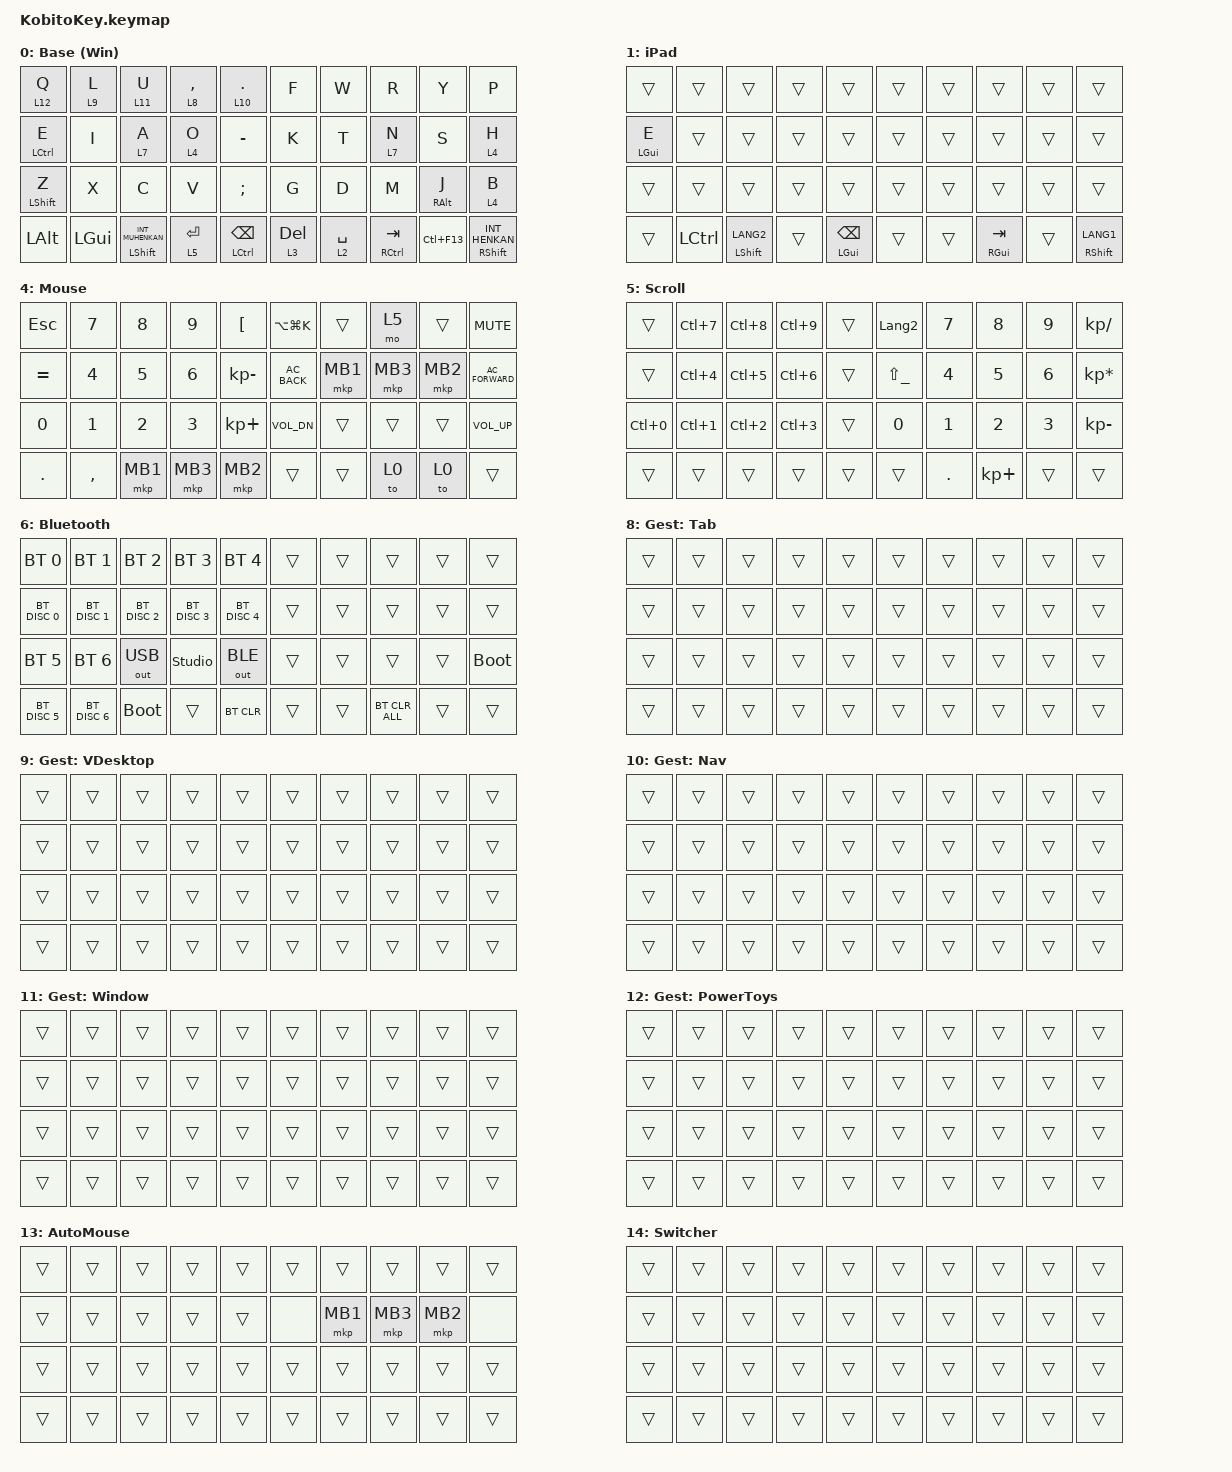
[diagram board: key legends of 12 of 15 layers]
/* 配列は torabo-tsuki LP (Daytona0306/zmk-keyboard-torabo-tsuki-lp) の移植。
 *
 * 文字キー30個は同じ位置。最下段は親指の内側から順に対応させた:
 *
 *   30 Alt   31 GUI   32 無変換/Shift  33 Enter/L5  34 BS/Ctrl
 *   35 Del/L3  36 Space/L2  37 変換/Shift   38 Ctrl+F13  39 Tab
 *
 * torabo-tsuki LP の外周・数字段・中央の追加キーは小人キーに無いので落としている。
 * レイヤー番号は torabo-tsuki LP と同じ (コンボ・ジェスチャー・overlay・conf が番号に依存)。 */
#include <behaviors.dtsi>
#include <dt-bindings/zmk/bt.h>
#include <dt-bindings/zmk/keys.h>
#include <dt-bindings/zmk/outputs.h>
#include <dt-bindings/zmk/pointing.h>
/* &rmacro <slot>。中身は DYA Studio のランタイムマクロパネルで記録する。 */
#include <behaviors/runtime_macro.dtsi>
/* &mg_set N。押している間だけ RPC 側のジェスチャーセットが有効になる。 */
#include <mouse-gesture-rpc.dtsi>

/* ジェスチャー定義は機種共通 (zmk-dya-common)。ジェスチャーは右ボール (カーソル側)。
 * BASE_LAYER は矢印ジェスチャーのレイヤー番号で、そこから連番で6枚使う。
 * TRANSFORM は 0 (変換なし): 右ボールのベースチェーンに軸反転が無いため。
 * ★実機未確認★ 上下左右が逆に出たらここを INPUT_TRANSFORM_*_INVERT にする。 */
#define DYA_GESTURE_LISTENER   tb_right_listener
#define DYA_GESTURE_BASE_LAYER 7
#define DYA_GESTURE_TRANSFORM  0
#include <dya-common/gestures.dtsi>

&mt {
    tapping-term-ms = <180>;
    quick-tap-ms = <300>;
    flavor = "tap-preferred";
    require-prior-idle-ms = <125>;
};

&lt {
    tapping-term-ms = <180>;
    quick-tap-ms = <300>;
    flavor = "tap-preferred";
    require-prior-idle-ms = <125>;
};

/* DYA Studio 用の「セット番号固定」ジェスチャーキー。
 *
 * Studio はパラメータ付きのカスタム behavior を保持できないため、汎用の
 * &mg_set N は Studio の一覧から割り当てられない。モジュール側は対策として
 * パラメータ無しの compatible "zmk,behavior-mg-set-fixed" を用意しているが、
 * ノード自体は定義していない (README にも記載なし) ので、ここで自前で作る。
 *
 * セット番号はノード名の末尾1文字から決まる (behavior_mg_set.c の
 * binding_set_id())。よってノード名は必ず _0 / _1 / _2 で終わらせること。
 * ドライバ側の判定が '0'..'2' 固定なので 3 セットまでしか作れない。
 *
 * 押している間だけジェスチャー判定が有効になり、離した時点で一致した
 * ジェスチャーが発火する。 */
/ {
    behaviors {
        mg_set_0: behavior_mg_set_0 {
            compatible = "zmk,behavior-mg-set-fixed";
            #binding-cells = <0>;
            display-name = "Mouse Gesture Key 0";
        };

        mg_set_1: behavior_mg_set_1 {
            compatible = "zmk,behavior-mg-set-fixed";
            #binding-cells = <0>;
            display-name = "Mouse Gesture Key 1";
        };

        mg_set_2: behavior_mg_set_2 {
            compatible = "zmk,behavior-mg-set-fixed";
            #binding-cells = <0>;
            display-name = "Mouse Gesture Key 2";
        };
    };
};

/* ジェスチャーキーの hold-tap 版。&mg_ht <セット> <キーコード> で
 * 「長押し＝ジェスチャー、タップ＝通常キー」になる。
 *
 * hold 側は固定版 (mg_set_0 等) ではなく汎用の &mg_set を使う。
 * hold-tap は子のメタデータを合成して自分の param1 の選択肢にするが、
 * 固定版は空メタデータなので param1 が選べなくなるため
 * (behavior_hold_tap.c の hold_tap_parameter_metadata())。
 * 汎用版ならセット番号が param1 としてそのまま渡り、名前末尾ではなく
 * パラメータ側で解決される。
 *
 * flavor は tap-preferred。ボールの動きは hold-tap の判定材料に
 * ならないため他フレーバーにする利点がなく、ストローク中に他キーへ
 * 触れても hold に化けないぶん安全。
 *
 * 制約: マッチャーが ON になるのは hold 確定後なので、押してから
 * tapping-term-ms のあいだのボール移動は通常のカーソル移動として出る。
 * 「押して即ストローク」はできない。専用キーに素の &mg_set を置いた
 * ほうが体感は良い。短くすると今度はタップを取りこぼす。 */
/ {
    behaviors {
        mg_ht: mouse_gesture_hold_tap {
            compatible = "zmk,behavior-hold-tap";
            #binding-cells = <2>;
            flavor = "tap-preferred";
            tapping-term-ms = <150>;
            bindings = <&mg_set>, <&kp>;
            display-name = "Mouse Gesture Hold-Tap";
        };
    };
};

/ {
    combos {
        compatible = "zmk,combos";

        tab {
            bindings = <&kp TAB>;
            key-positions = <10 11>;
        };

        esc {
            bindings = <&kp ESCAPE>;
            key-positions = <0 1>;
        };

        caps {
            bindings = <&kp CAPSLOCK>;
            key-positions = <20 21>;
        };

        BS {
            bindings = <&kp BACKSPACE>;
            key-positions = <8 9>;
        };

        LANG_2 {
            bindings = <&kp LANGUAGE_2>;
            key-positions = <12 13>;
        };

        LANG_1 {
            bindings = <&kp LANGUAGE_1>;
            key-positions = <16 17>;
        };

        Layer_6 {
            bindings = <&mo 6>;
            key-positions = <26 27>;
        };

        Layer_4 {
            bindings = <&mo 5>;
            key-positions = <27 28>;
        };

        /* Ctrl+Alt+Tab (Windows の固定タスクスイッチャー)。
         *
         * ★押した瞬間に Ctrl+Alt+Tab を1回だけ送って切り替え画面を開き、押している間は
         *   レイヤー 14 (Switcher) で左ボールが矢印キーになる (選択を動かす)。
         *   離すと Enter で決定する。中身は下の macros の win_switcher。
         *   以前は &kp LA(LC(TAB)) で押しっぱなしにしていたため、キーリピートで選択が右へ流れていた。
         *
         * ★このコンボは DYA Studio 側にも同じ内容で入れてある。
         *   そちらを有効にしていると毎回発動し、無効にすると効いたり
         *   効かなかったりする、という実機の結果がある。
         *   両方に同じ内容があるのは意図的。片方だけ直さないこと。
         *   経緯は README「コンボが keymap と DYA Studio の両方にあるとき、
         *   勝つ側はリンク順で決まる」と「同じコンボでも、DYA 側で持たせた
         *   ほうが安定することがある」。原因は未解明のまま打ち切った。
         *
         * timeout-ms は既定の 50 から広げてある。
         * これは上記の差の説明ではない (ランタイム側の既定も 50 で、
         * 2キーコンボの処理経路は両エンジンで等価)。
         * 純粋に、2/3 が上段の2キー同時押しで、ホームポジションにある
         * LANG_2 (12/13) より指が揃いにくいことへの手当て。
         *
         * 広げるコストは小さい。combo.c の position_state_up は離した時点で
         * cleanup() を呼んで取り込んだイベントを流すので、普通に U を打つぶんには
         * タイムアウトを待たされない。長押しでレイヤーに入るときだけ
         * timeout-ms 分だけ遅れる (200 + 80 = 280ms)。 */
        combo_ctrl_alt_tab {
            key-positions = <2 3>;
            bindings = <&win_switcher>;
            timeout-ms = <80>;
        };
    };

    macros {
        BrowsToExploree: BrowsToExploree {
            compatible = "zmk,behavior-macro";
            #binding-cells = <0>;
            bindings = <&kp LS(LA(B)) &kp ENTER &kp LG(NUMBER_1)>;
            label = "BROWSTOEXPLOREE";
        };

        /* ウィンドウ切り替え (Ctrl+Alt+Tab コンボ用)。
         * 押す: Ctrl+Alt+Tab を1回 → レイヤー 14 (Switcher) を有効にする
         * 押している間: 左ボールの上下左右が矢印キー (KobitoKey_left.overlay の route_switcher)
         * 離す: レイヤー 14 を切って Enter (選んだウィンドウに切り替わる) */
        win_switcher: win_switcher {
            compatible = "zmk,behavior-macro";
            #binding-cells = <0>;
            label = "WIN_SWITCHER";
            bindings
                = <&macro_tap &kp LC(LA(TAB))>
                , <&macro_press &mo 14>
                , <&macro_pause_for_release>
                , <&macro_release &mo 14>
                , <&macro_tap &kp ENTER>
                ;
        };

        to_layer_0: to_layer_0 {
            compatible = "zmk,behavior-macro-one-param";
            #binding-cells = <1>;
            bindings = <&to 0 &macro_param_1to1 &kp MACRO_PLACEHOLDER>;
            label = "TO_LAYER_0";
        };

    };

    behaviors {
        /* 文字キーの長押しでジェスチャーレイヤー (7〜12) に入るキー用の layer-tap。
         * A・N・Q・L・U・,・. に使う。親指 (Space/Del/Enter) と O/H/B (Mouse) は &lt のまま。
         *
         * 文字キーは打鍵中に頻繁に出るので、&lt より誤爆しにくい側に倒している。
         * 例: 寿司打で「ni」の N を少し長めに押すと、レイヤー 7 の I の位置の F5 が出て
         * ページが再読み込みされていた。
         *   - tapping-term 250ms: これより短く離せばタップ (tap-preferred なので押している長さだけで決まる)
         *   - require-prior-idle 200ms: 直前の打鍵から 200ms 以内に押したら、長押し判定をせずタップに確定
         * DYA Studio の dya__holdtap (mt/lt だけが対象) では変えられない。変えるときはここを書き換えて焼く。 */
        lt_gest: lt_gest {
            compatible = "zmk,behavior-hold-tap";
            display-name = "Layer-Tap (Gesture)";
            #binding-cells = <2>;
            bindings = <&mo>, <&kp>;
            flavor = "tap-preferred";
            tapping-term-ms = <250>;
            quick-tap-ms = <300>;
            require-prior-idle-ms = <200>;
        };

        lt_to_layer_0: lt_to_layer_0 {
            compatible = "zmk,behavior-hold-tap";
            label = "LAYER_TAP_TO_0";
            bindings = <&mo>, <&to_layer_0>;

            #binding-cells = <2>;
            tapping-term-ms = <180>;
        };
    };

    keymap {
        compatible = "zmk,keymap";

        default_layer {
            display-name = "Base (Win)";
            bindings = <
&lt_gest 12 Q     &lt_gest 9 L  &lt_gest 11 U                &lt_gest 8 COMMA  &lt_gest 10 PERIOD              &kp F      &kp W        &kp R                  &kp Y            &kp P
&mt LCTRL E       &kp I         &lt_gest 7 A                 &lt 4 O           &kp MINUS                       &kp K      &kp T        &lt_gest 7 N           &kp S            &lt 4 H
&mt LEFT_SHIFT Z  &kp X         &kp C                        &kp V             &kp SEMICOLON                   &kp G      &kp D        &kp M                  &mt RIGHT_ALT J  &lt 4 B
&kp LEFT_ALT      &kp LGUI      &mt LEFT_SHIFT INT_MUHENKAN  &lt 5 ENTER       &mt LEFT_CONTROL BACKSPACE      &lt 3 DEL  &lt 2 SPACE  &mt RIGHT_CONTROL TAB  &kp LC(F13)      &mt RIGHT_SHIFT INT_HENKAN
            >;
        };

        /* index 1: iPad / iOS 用ベースレイヤー。差分だけ書く (&trans はレイヤー0に落ちる)。
         * 置き場所は必ず 1。末尾に置くと常時 ON のこのレイヤーが機能レイヤーを
         * 全部上書きする。経緯は torabo-tsuki LP の keymap / README を参照。 */
        iPad {
            display-name = "iPad";
            bindings = <
&trans      &trans     &trans                &trans  &trans                      &trans  &trans  &trans             &trans  &trans
&mt LGUI E  &trans     &trans                &trans  &trans                      &trans  &trans  &trans             &trans  &trans
&trans      &trans     &trans                &trans  &trans                      &trans  &trans  &trans             &trans  &trans
&trans      &kp LCTRL  &mt LEFT_SHIFT LANG2  &trans  &mt LEFT_GUI BACKSPACE      &trans  &trans  &mt RIGHT_GUI TAB  &trans  &mt RIGHT_SHIFT LANG1
            >;
        };

        NUM,SYM1 {
            display-name = "NUM/SYM1";
            bindings = <
&kp NUMBER_1              &kp NUMBER_2              &kp NUMBER_3               &kp NUMBER_4   &kp N5                       &kp NUMBER_6   &kp N7                &kp N8             &kp N9                &kp N0
&kp EQUAL                 &kp LEFT_BRACKET          &kp SLASH                  &kp MINUS      &kp LS(INTERNATIONAL_1)      &kp SEMICOLON  &kp SQT               &kp RIGHT_BRACKET  &kp BACKSLASH         &kp INT_YEN
&kp LS(LA(LC(NUMBER_2)))  &kp LS(LC(LA(NUMBER_6)))  &kp PRINTSCREEN            &kp LS(LG(S))  &kp LA(PRINTSCREEN)          &kp CAPSLOCK   &kp LS(LC(NUMBER_2))  &kp LS(LC(I))      &kp LS(LC(NUMBER_1))  &kp SCROLLLOCK
&trans                    &trans                    &mt LEFT_SHIFT LANGUAGE_1  &kp LG(LS(V))  &trans                       &trans         &trans                &to 4              &trans                &trans
            >;
        };

        SYM2 {
            display-name = "SYM2";
            bindings = <
&kp LS(NUMBER_1)   &kp LS(NUMBER_2)    &kp LS(NUMBER_3)           &kp LS(NUMBER_4)    &kp LS(N5)                   &kp LS(NUMBER_6)        &kp LS(N7)               &kp LS(N8)             &kp LS(N9)                  &kp LS(N0)
&kp LS(EQUAL)      &kp LS(LEFT_BRACE)  &kp QUESTION               &kp LS(UNDERSCORE)  &kp LS(INTERNATIONAL_1)      &kp LS(SEMICOLON)       &kp LS(SQT)              &kp LS(RIGHT_BRACKET)  &kp LS(BACKSLASH)           &kp LS(INT_YEN)
&kp LS(LA(MINUS))  &trans              &trans                     &BrowsToExploree    &rmacro 1                    &kp LC(LG(LEFT_ARROW))  &kp LC(LG(RIGHT_ARROW))  &kp LA(LC(LG(D)))      &kp LC(LA(LG(LEFT_ARROW)))  &kp LA(LC(LG(RIGHT_ARROW)))
&trans             &trans              &mt LEFT_SHIFT LANGUAGE_2  &trans              &trans                       &trans                  &trans                   &kp LC(LG(F4))         &trans                      &trans
            >;
        };

        /* 戻る/進むはマウスボタン (MB4/MB5) ではなく、キーボードの戻る/進むキー (C_AC_BACK / C_AC_FORWARD)。
         * MB4/MB5 は PC 側のジェスチャーソフトに割り当てていて、別の操作になるため。 */
        MOUSE {
            display-name = "Mouse";
            bindings = <
&kp ESCAPE  &kp N7     &kp N8    &kp N9    &kp LBKT          &kp LA(LG(K))  &trans    &mo 5     &trans    &kp C_MUTE
&kp EQUAL   &kp N4     &kp N5    &kp N6    &kp KP_MINUS      &kp C_AC_BACK  &mkp MB1  &mkp MB3  &mkp MB2  &kp C_AC_FORWARD
&kp N0      &kp N1     &kp N2    &kp N3    &kp KP_PLUS       &kp C_VOL_DN   &trans    &trans    &trans    &kp C_VOL_UP
&kp DOT     &kp COMMA  &mkp MB1  &mkp MB3  &mkp MB2          &trans         &trans    &to 0     &to 0     &trans
            >;
        };

        NUM-SCROLL {
            display-name = "Scroll";
            bindings = <
&trans      &kp LC(N7)        &kp LC(N8)        &kp LC(N9)        &trans      &kp LANGUAGE_2      &kp N7        &kp N8        &kp N9        &kp KP_SLASH
&trans      &kp LC(NUMBER_4)  &kp LC(N5)        &kp LC(NUMBER_6)  &trans      &kp LS(UNDERSCORE)  &kp NUMBER_4  &kp N5        &kp NUMBER_6  &kp KP_MULTIPLY
&kp LC(N0)  &kp LC(NUMBER_1)  &kp LC(NUMBER_2)  &kp LC(NUMBER_3)  &trans      &kp N0              &kp NUMBER_1  &kp NUMBER_2  &kp NUMBER_3  &kp KP_MINUS
&trans      &trans            &trans            &trans            &trans      &trans              &kp DOT       &kp KP_PLUS   &trans        &trans
            >;
        };

        bluetooth {
            display-name = "Bluetooth";
            bindings = <
&bt BT_SEL 0   &bt BT_SEL 1   &bt BT_SEL 2   &bt BT_SEL 3    &bt BT_SEL 4       &trans  &trans  &trans          &trans  &trans
&bt BT_DISC 0  &bt BT_DISC 1  &bt BT_DISC 2  &bt BT_DISC 3   &bt BT_DISC 4      &trans  &trans  &trans          &trans  &trans
&bt BT_SEL 5   &bt BT_SEL 6   &out OUT_USB   &studio_unlock  &out OUT_BLE       &trans  &trans  &trans          &trans  &bootloader
&bt BT_DISC 5  &bt BT_DISC 6  &bootloader    &trans          &bt BT_CLR         &trans  &trans  &bt BT_CLR_ALL  &trans  &trans
            >;
        };

        gest_arrow {
            display-name = "Gest: Arrow";
            bindings = <
&kp ESC  &kp F1  &kp F2   &kp F3   &kp F4       &kp INS        &kp HOME        &kp UP_ARROW    &kp END          &kp PG_UP
&trans   &kp F5  &kp F6   &kp F7   &kp F8       &kp LC(TAB)    &kp LEFT_ARROW  &kp UP_ARROW    &kp RIGHT_ARROW  &kp PAGE_DOWN
&trans   &kp F9  &kp F10  &kp F11  &kp F12      &kp LG(LS(V))  &kp LEFT_ARROW  &kp DOWN_ARROW  &kp RIGHT_ARROW  &kp LC(LG(LA(V)))
&trans   &trans  &trans   &trans   &trans       &trans         &trans          &trans          &trans           &trans
            >;
        };

        gest_tab {
            display-name = "Gest: Tab";
            bindings = <
&trans  &trans  &trans  &trans  &trans      &trans  &trans  &trans  &trans  &trans
&trans  &trans  &trans  &trans  &trans      &trans  &trans  &trans  &trans  &trans
&trans  &trans  &trans  &trans  &trans      &trans  &trans  &trans  &trans  &trans
&trans  &trans  &trans  &trans  &trans      &trans  &trans  &trans  &trans  &trans
            >;
        };

        gest_vdesktop {
            display-name = "Gest: VDesktop";
            bindings = <
&trans  &trans  &trans  &trans  &trans      &trans  &trans  &trans  &trans  &trans
&trans  &trans  &trans  &trans  &trans      &trans  &trans  &trans  &trans  &trans
&trans  &trans  &trans  &trans  &trans      &trans  &trans  &trans  &trans  &trans
&trans  &trans  &trans  &trans  &trans      &trans  &trans  &trans  &trans  &trans
            >;
        };

        gest_nav {
            display-name = "Gest: Nav";
            bindings = <
&trans  &trans  &trans  &trans  &trans      &trans  &trans  &trans  &trans  &trans
&trans  &trans  &trans  &trans  &trans      &trans  &trans  &trans  &trans  &trans
&trans  &trans  &trans  &trans  &trans      &trans  &trans  &trans  &trans  &trans
&trans  &trans  &trans  &trans  &trans      &trans  &trans  &trans  &trans  &trans
            >;
        };

        gest_window {
            display-name = "Gest: Window";
            bindings = <
&trans  &trans  &trans  &trans  &trans      &trans  &trans  &trans  &trans  &trans
&trans  &trans  &trans  &trans  &trans      &trans  &trans  &trans  &trans  &trans
&trans  &trans  &trans  &trans  &trans      &trans  &trans  &trans  &trans  &trans
&trans  &trans  &trans  &trans  &trans      &trans  &trans  &trans  &trans  &trans
            >;
        };

        gest_powertoys {
            display-name = "Gest: PowerToys";
            bindings = <
&trans  &trans  &trans  &trans  &trans      &trans  &trans  &trans  &trans  &trans
&trans  &trans  &trans  &trans  &trans      &trans  &trans  &trans  &trans  &trans
&trans  &trans  &trans  &trans  &trans      &trans  &trans  &trans  &trans  &trans
&trans  &trans  &trans  &trans  &trans      &trans  &trans  &trans  &trans  &trans
            >;
        };

        /* index 13: オートマウス (右ボールを動かすと自動で入る)。
         * 入り方・抜け方は boards/shields/KobitoKey/kobitokey.dtsi の
         * mouse_runtime_input_processor (temp-layer-*) で決めている。DYA Studio でも変えられる。
         * クリックは右手中段 T N S (左・中・右、Mouse レイヤー (4) と同じ位置)。K と H は &none (何も出さない)。
         * 左親指 (無変換・Enter・BS) には置かない: 置くと選択後の BS などがクリックに化け、レイヤーからも抜けない。
         * それ以外は &trans にしておくこと:
         * &trans のキー (修飾キーを除く) を押すとこのレイヤーから抜け、押した文字はそのまま出る。
         * &trans 以外を置いたキーは押しても抜けない (Mouse レイヤーに自動で入らないのはこのため)。 */
        auto_mouse {
            display-name = "AutoMouse";
            bindings = <
&trans  &trans  &trans  &trans  &trans      &trans    &trans    &trans    &trans    &trans
&trans  &trans  &trans  &trans  &trans      &none      &mkp MB1  &mkp MB3  &mkp MB2  &none
&trans  &trans  &trans  &trans  &trans      &trans    &trans    &trans    &trans    &trans
&trans  &trans  &trans  &trans  &trans      &trans    &trans    &trans    &trans    &trans
            >;
        };

        /* index 14: ウィンドウ切り替え中 (Ctrl+Alt+Tab コンボを押している間だけ)。
         * キーは全部 &trans。左ボールを矢印キーにするためだけのレイヤー。 */
        switcher {
            display-name = "Switcher";
            bindings = <
&trans  &trans  &trans  &trans  &trans      &trans  &trans  &trans  &trans  &trans
&trans  &trans  &trans  &trans  &trans      &trans  &trans  &trans  &trans  &trans
&trans  &trans  &trans  &trans  &trans      &trans  &trans  &trans  &trans  &trans
&trans  &trans  &trans  &trans  &trans      &trans  &trans  &trans  &trans  &trans
            >;
        };
    };
};
